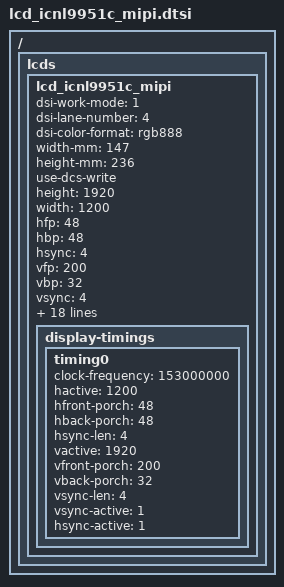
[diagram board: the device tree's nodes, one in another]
// SPDX-License-Identifier: GPL-2.0

/ { lcds: lcds {
	lcd_icnl9951c_mipi: lcd_icnl9951c_mipi {
		dsi-work-mode = <1>; /* video burst mode*/
		dsi-lane-number = <4>;
		dsi-color-format = "rgb888";
		width-mm = <147>;
		height-mm = <236>;
		use-dcs-write;

		/*mipi info*/
		height = <1920>;
		width = <1200>;
		hfp = <48>;
		hbp = <48>;
		hsync = <4>;
		vfp = <200>;
		vbp = <32>;
		vsync = <4>;
		fps = <60>;
		work-mode = <0>;
		rgb-mode = <3>;
		lane-number = <4>;
		phy-bit-clock = <1000000000>;
		phy-esc-clock = <76800000>;
		split-enable = <0>;
		eotp-enable = <0>;
		burst-mode = <2>;
		esd-check-enable = <0>;

		/* DSI_CMD, DSI_MODE, timeout, len, cmd */
		initial-command = [
			39 01 00 04 F0 99 51 0C
			39 01 00 10 B2 03 02 10 10 66 66 09 03 46 00 0F 80 80 80 80
			39 01 00 17 B3 73 01 05 84 00 96 00 71 00 00 00 00 00 00 11 88 06 44 00 01 00 00
			39 01 00 0D B4 19 0B 06 0B 06 01 A2 30 44 E6 26 00
			39 01 00 20 B5 80 80 B6 B6 B7 B7 43 43 97 97 95 95 93 93 91 91 B1 B1 83 83 83 83 0F 00 00 00 01 50 FF FF FC
			39 01 00 20 B6 80 80 B6 B6 B7 B7 43 43 96 96 94 94 92 92 90 90 B0 B0 83 83 83 83 0F 00 00 00 05 50 FF FF FC
			39 01 00 17 B7 50 50 50 50 50 50 5F 5F 50 50 50 50 50 50 50 50 50 50 55 55 55 55
			39 01 00 19 B8 0F 0F 00 00 05 50 0F 0F 00 00 05 50 FF FF FF FF F5 50 FF FF FF FF F5 50
			39 01 00 19 B9 0F 0F 00 00 05 50 0F 0F 00 00 05 50 FF FF FF FF F5 50 FF FF FF FF F5 50
			39 01 00 10 BB 01 02 03 0A 04 13 14 12 16 5C 00 15 16 03 82
			39 01 00 1A BC FE BC F0 22 02 22 00 04 00 27 B2 06 23 12 99 AA A9 0A 00 87 CB 06 03 27 11
			39 01 00 08 BD ED 23 42 52 2A 02 1F
			39 01 00 11 BE 68 54 6E 50 88 88 22 CC 9C 77 77 77 99 00 00 30
			39 01 00 0B BF 0C 19 0C 00 00 11 22 04 0F 07
			39 01 00 17 C1 00 C8 00 20 04 30 30 04 07 80 02 58 01 11 C0 44 07 91 FF 4C 0F E7
			39 01 00 03 C2 00 00
			39 01 00 0D C3 00 FF AA 5D 06 00 FF 27 A8 08 80 00
			39 01 00 0F C4 04 AA 28 49 00 3F 00 00 0E F0 EF C0 D4 01
			39 01 00 0C C5 00 00 C3 A0 80 80 12 FF 00 0A 0B
			39 01 00 08 C8 42 00 00 87 C0 00 03
			39 01 00 07 D7 3F 06 0A 00 00 0F
			39 01 00 09 D1 10 10 10 10 10 34 28 18
			39 01 00 1D C7 77 77 77 77 77 77 77 77 70 77 77 77 77 77 77 77 77 72 42 00 00 A9 FA FA 00 E7 00 7E
			39 01 00 21 80 FA F4 EB E4 DD D8 D3 CE CA BC B1 A7 A0 98 92 87 7E 76 6E 6D 66 5E 56 4D 48 42 3B 33 2A 1D 19 15
			39 01 00 21 81 FA F4 EB E4 DD D8 D3 CE CA BC B1 A7 A0 98 92 87 7E 76 6E 6D 66 5E 56 4D 48 42 3B 33 2A 1D 19 15
			39 01 00 21 82 FA F4 EB E4 DD D8 D3 CE CA BC B1 A7 A0 98 92 87 7E 76 6E 6D 66 5E 56 4D 48 42 3B 33 2A 1D 19 15
			39 01 00 14 83 09 11 0C 07 03 00 00 11 0C 07 03 00 00 11 0C 07 03 00 00
			39 01 00 1F 84 3D C2 57 3B 42 3F BF 1E 14 40 3D C2 57 3B 42 3F BF 1E 14 40 3D C2 57 3B 42 3F BF 1E 14 40
			39 01 00 05 D4 20 30 65 00
			39 01 00 05 D5 01 30 A9 11
			39 01 00 04 F0 99 51 00
			39 01 00 02 35 00
			39 01 64 02 53 2C
			39 01 78 01 11
			39 01 78 01 29
			39 01 00 02 AC 05
		];
		sleep-in-command = [
			39 01 00 02 AC 0A
			39 01 78 01 28
			39 01 78 01 10
		];
		sleep-out-command = [
			39 01 78 01 11
			39 01 78 01 29
		];
		read-id-command = [
			37 01 00 01 01
			14 01 00 01 04
		];

		display-timings {
			timing0 {
				clock-frequency = <153000000>;
				hactive = <1200>;
				hfront-porch = <48>;
				hback-porch = <48>;
				hsync-len = <4>;
				vactive = <1920>;
				vfront-porch = <200>;
				vback-porch = <32>;
				vsync-len = <4>;
				vsync-active = <1>;
				hsync-active = <1>;
			};
		};
	};
};};
